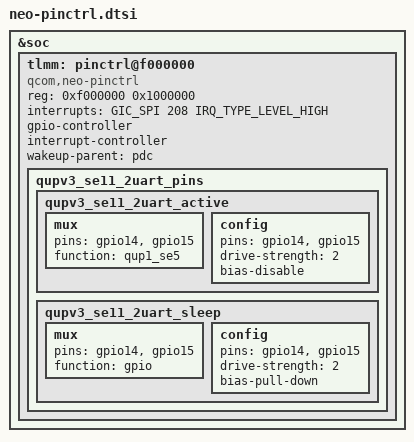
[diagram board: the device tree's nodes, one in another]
&soc {
	tlmm: pinctrl@f000000 {
		compatible = "qcom,neo-pinctrl";
		reg = <0xf000000 0x1000000>;
		interrupts = <GIC_SPI 208 IRQ_TYPE_LEVEL_HIGH>;
		gpio-controller;
		#gpio-cells = <2>;
		interrupt-controller;
		#interrupt-cells = <2>;
		wakeup-parent = <&pdc>;

		qupv3_se11_2uart_pins: qupv3_se11_2uart_pins {
			qupv3_se11_2uart_active: qupv3_se11_2uart_active {
				mux {
					pins = "gpio14","gpio15";
					function = "qup1_se5";
				};

				config {
					pins = "gpio14","gpio15";
					drive-strength = <2>;
					bias-disable;
				};
			};

			qupv3_se11_2uart_sleep: qupv3_se11_2uart_sleep {
				mux {
					pins = "gpio14", "gpio15";
					function = "gpio";
				};

				config {
					pins = "gpio14", "gpio15";
					drive-strength = <2>;
					bias-pull-down;
				};
			};
		};

	};
};
